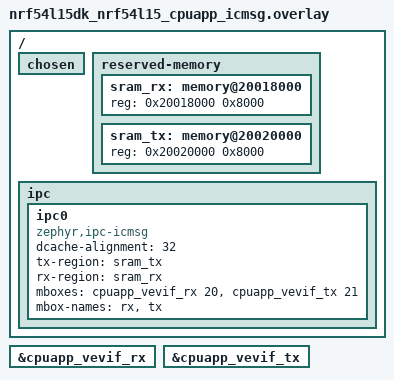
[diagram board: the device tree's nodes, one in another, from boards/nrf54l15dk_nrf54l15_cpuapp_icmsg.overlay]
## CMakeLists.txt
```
#
# Copyright (c) 2022 Nordic Semiconductor
#
# SPDX-License-Identifier: LicenseRef-Nordic-5-Clause
#

cmake_minimum_required(VERSION 3.20.0)

find_package(Zephyr REQUIRED HINTS $ENV{ZEPHYR_BASE})
project(event_manager_proxy)

add_subdirectory(common_config)
add_subdirectory(common_events)
add_subdirectory(modules)

target_include_directories(app PUBLIC ${CMAKE_CURRENT_SOURCE_DIR}/src)

target_sources(app PRIVATE
  src/test_init.c
  src/data.c
  src/simple.c
)
```

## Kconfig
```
#
# Copyright (c) 2022 Nordic Semiconductor ASA
#
# SPDX-License-Identifier: LicenseRef-Nordic-5-Clause
#

menu "Zephyr Kernel"
source "Kconfig.zephyr"
endmenu

menu "Event manager proxy test settings"

config APP_SYSTEM_INIT_PRIO
	int "The application preparation initializaition priority"
	default 0
	help
	  The priority of initialization of everything that have to happen
	  before the proxy initialation.
	  The remote core is initialized here if required.

config APP_PROXY_INIT_PRIO
	int "Proxy initialization priority"
	default 1
	help
	  The Event manager proxy initialization priority.
	  Make sure that initialization happens before registration and starting.

config APP_PROXY_REGISTER_PRIO
	int "Proxy registration priority"
	default 2
	help
	  The Event manager proxy registration priority.
	  The moment when all the modules reqisters to the required events to remote.
	  Make sure that it happens after the proxy itself is initialized but before
	  it is started.

config APP_PROXY_START_PRIO
	int "Proxy start priority"
	default 5
	help
	  The Event manager proxy starting priority.
	  The moment when Event manager is started.
	  After this time no more remote event registration is allowed.
	  Make sure that it happens after event proxy registration.

rsource "common_events/Kconfig"
endmenu
```

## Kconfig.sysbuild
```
#
# Copyright (c) 2023 Nordic Semiconductor ASA
#
# SPDX-License-Identifier: LicenseRef-Nordic-5-Clause
#

if SUPPORT_PPRCORE

choice PPRCORE
	default PPRCORE_REMOTE

config PPRCORE_REMOTE
	bool "remote image"

endchoice

config PPRCORE_IMAGE_NAME
	default "remote" if PPRCORE_REMOTE

config PPRCORE_IMAGE_PATH
	default "${APP_DIR}/remote" if PPRCORE_REMOTE

endif # SUPPORT_PPRCORE

if SUPPORT_FLPRCORE && !SUPPORT_PPRCORE

choice FLPRCORE
	default FLPRCORE_REMOTE

config FLPRCORE_REMOTE
	bool "remote image"

endchoice

config FLPRCORE_IMAGE_NAME
	default "remote" if FLPRCORE_REMOTE

config FLPRCORE_IMAGE_PATH
	default "${APP_DIR}/remote" if FLPRCORE_REMOTE

endif # SUPPORT_FLPRCORE && !SUPPORT_PPRCORE

if SUPPORT_NETCORE && !SUPPORT_FLPRCORE && !SUPPORT_PPRCORE

choice NETCORE
	default NETCORE_REMOTE

config NETCORE_REMOTE
	bool "remote image"

endchoice

config NETCORE_IMAGE_NAME
	default "remote" if NETCORE_REMOTE

config NETCORE_IMAGE_PATH
	default "${APP_DIR}/remote" if NETCORE_REMOTE

endif # SUPPORT_NETCORE && !SUPPORT_FLPRCORE && !SUPPORT_PPRCORE

source "share/sysbuild/Kconfig"
```

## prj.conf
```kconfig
#
# Copyright (c) 2022-2023 Nordic Semiconductor ASA
#
# SPDX-License-Identifier: LicenseRef-Nordic-5-Clause
#

CONFIG_ZTEST=y

CONFIG_ENTROPY_GENERATOR=y

# Configuration required by Application Event Manager
CONFIG_APP_EVENT_MANAGER=y
CONFIG_EVENT_MANAGER_PROXY=y
CONFIG_SYSTEM_WORKQUEUE_STACK_SIZE=2048
CONFIG_HEAP_MEM_POOL_SIZE=2048

CONFIG_IPC_SERVICE=y
CONFIG_MBOX=y

# Custom reboot handler is implemented for test purposes
CONFIG_RESET_ON_FATAL_ERROR=n
CONFIG_REBOOT=n

###################################
# Application configuration
###################################

CONFIG_APP_DATA_EVENT=y
CONFIG_APP_SIMPLE_EVENT=y
CONFIG_APP_TEST_EVENT=y
```

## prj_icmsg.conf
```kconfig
#
# Copyright (c) 2022-2023 Nordic Semiconductor ASA
#
# SPDX-License-Identifier: LicenseRef-Nordic-5-Clause
#

CONFIG_ZTEST=y

CONFIG_ENTROPY_GENERATOR=y

# Configuration required by Application Event Manager
CONFIG_APP_EVENT_MANAGER=y
CONFIG_EVENT_MANAGER_PROXY=y
CONFIG_SYSTEM_WORKQUEUE_STACK_SIZE=2048
CONFIG_HEAP_MEM_POOL_SIZE=2048

CONFIG_IPC_SERVICE=y
CONFIG_MBOX=y
CONFIG_PBUF_RX_READ_BUF_SIZE=512

CONFIG_EVENT_MANAGER_PROXY_SEND_RETRIES=100

# Custom reboot handler is implemented for test purposes
CONFIG_RESET_ON_FATAL_ERROR=n
CONFIG_REBOOT=n

###################################
# Application configuration
###################################

CONFIG_APP_DATA_EVENT=y
CONFIG_APP_SIMPLE_EVENT=y
CONFIG_APP_TEST_EVENT=y
```

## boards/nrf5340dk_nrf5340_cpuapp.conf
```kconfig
#
# Copyright (c) 2022 Nordic Semiconductor ASA
#
# SPDX-License-Identifier: LicenseRef-Nordic-5-Clause
#

CONFIG_SOC_NRF53_CPUNET_ENABLE=y
CONFIG_EVENT_MANAGER_PROXY_BIND_TIMEOUT_MS=4000
```

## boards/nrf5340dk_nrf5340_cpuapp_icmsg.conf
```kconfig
#
# Copyright (c) 2022 Nordic Semiconductor ASA
#
# SPDX-License-Identifier: LicenseRef-Nordic-5-Clause
#

CONFIG_SOC_NRF53_CPUNET_ENABLE=y
```

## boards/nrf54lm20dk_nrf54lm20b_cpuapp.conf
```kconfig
#
# Copyright (c) 2026 Nordic Semiconductor ASA
#
# SPDX-License-Identifier: LicenseRef-Nordic-5-Clause
#

CONFIG_EVENT_MANAGER_PROXY_BIND_TIMEOUT_MS=4000
```

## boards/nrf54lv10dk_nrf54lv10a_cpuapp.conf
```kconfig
#
# Copyright (c) 2025 Nordic Semiconductor ASA
#
# SPDX-License-Identifier: LicenseRef-Nordic-5-Clause
#

CONFIG_EVENT_MANAGER_PROXY_BIND_TIMEOUT_MS=4000
```

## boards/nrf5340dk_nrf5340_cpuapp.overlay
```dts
/*
 * Copyright (c) 2022 Nordic Semiconductor ASA
 *
 * SPDX-License-Identifier: LicenseRef-Nordic-5-Clause
 */
#include <zephyr/dt-bindings/ipc_service/static_vrings.h>

&ipc0 {
	zephyr,priority = <0 PRIO_PREEMPT>;
};
```

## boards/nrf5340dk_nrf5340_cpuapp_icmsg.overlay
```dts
/*
 * Copyright (c) 2022 Nordic Semiconductor ASA
 *
 * SPDX-License-Identifier: LicenseRef-Nordic-5-Clause
 */

/delete-node/ &ipc0;
/delete-node/ &sram0_shared;

/ {
	chosen {
		/delete-property/ zephyr,ipc_shm;
		/delete-property/ zephyr,bt-hci;
	};

	reserved-memory {
		#address-cells = <1>;
		#size-cells = <1>;
		ranges;

		sram_tx: memory@20070000 {
			reg = <0x20070000 0x0800>;
		};

		sram_rx: memory@20078000 {
			reg = <0x20078000 0x0800>;
		};
	};

	ipc0: ipc0 {
		compatible = "zephyr,ipc-icmsg";
		tx-region = <&sram_tx>;
		rx-region = <&sram_rx>;
		mboxes = <&mbox 0>, <&mbox 1>;
		mbox-names = "tx", "rx";
		status = "okay";
	};
};
```

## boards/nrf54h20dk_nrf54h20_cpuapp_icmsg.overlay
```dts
/*
 * Copyright (c) 2025 Nordic Semiconductor ASA
 *
 * SPDX-License-Identifier: LicenseRef-Nordic-5-Clause
 */

/* Replace default ipc0 instance */
/delete-node/ &ipc0;

/* Enabled nodes required by IPC
 * Mbox for PPR target, one for each side and one IPC instance
 */

&cpuppr_vevif {
	status = "okay";
};

ipc0: &cpuapp_cpuppr_ipc {
	status = "okay";
};

/ {
	chosen {
		/delete-property/ zephyr,bt-hci;
	};
};
```

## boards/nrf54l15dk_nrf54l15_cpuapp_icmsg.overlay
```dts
/*
 * Copyright (c) 2025 Nordic Semiconductor ASA
 *
 * SPDX-License-Identifier: LicenseRef-Nordic-5-Clause
 */

/ {
	chosen {
		/delete-property/ zephyr,bt-hci;
	};

	reserved-memory {
		#address-cells = <1>;
		#size-cells = <1>;
		ranges;

		sram_rx: memory@20018000 {
			reg = <0x20018000 0x8000>;
		};

		sram_tx: memory@20020000 {
			reg = <0x20020000 0x8000>;
		};
	};

	ipc {
		ipc0: ipc0 {
			compatible = "zephyr,ipc-icmsg";
			/delete-property/ tx-blocks;
			/delete-property/ rx-blocks;
			dcache-alignment = <32>;
			tx-region = <&sram_tx>;
			rx-region = <&sram_rx>;
			mboxes = <&cpuapp_vevif_rx 20>, <&cpuapp_vevif_tx 21>;
			mbox-names = "rx", "tx";
			status = "okay";
		};
	};
};

&cpuapp_vevif_rx {
	status = "okay";
};

&cpuapp_vevif_tx {
	status = "okay";
};
```

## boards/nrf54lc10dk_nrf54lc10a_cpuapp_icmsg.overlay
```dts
/*
 * Copyright (c) 2026 Nordic Semiconductor ASA
 *
 * SPDX-License-Identifier: LicenseRef-Nordic-5-Clause
 */

/ {
	chosen {
		/delete-property/ zephyr,bt-hci;
	};

	reserved-memory {
		#address-cells = <1>;
		#size-cells = <1>;
		ranges;

		sram_rx: memory@2000fc00 {
			reg = <0x2000fc00 0x8000>;
		};

		sram_tx: memory@20017c00 {
			reg = <0x20017c00 0x8000>;
		};
	};

	ipc {
		ipc0: ipc0 {
			compatible = "zephyr,ipc-icmsg";
			dcache-alignment = <32>;
			tx-region = <&sram_tx>;
			rx-region = <&sram_rx>;
			mboxes = <&cpuapp_vevif_rx 20>, <&cpuapp_vevif_tx 21>;
			mbox-names = "rx", "tx";
			status = "okay";
		};
	};
};

&cpuapp_vevif_rx {
	status = "okay";
};

&cpuapp_vevif_tx {
	status = "okay";
};
```

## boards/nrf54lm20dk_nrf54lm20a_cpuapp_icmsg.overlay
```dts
/*
 * Copyright (c) 2025 Nordic Semiconductor ASA
 *
 * SPDX-License-Identifier: LicenseRef-Nordic-5-Clause
 */

/ {
	chosen {
		/delete-property/ zephyr,bt-hci;
	};

	reserved-memory {
		#address-cells = <1>;
		#size-cells = <1>;
		ranges;

		sram_rx: memory@20057c00 {
			reg = <0x20057c00 0x8000>;
		};

		sram_tx: memory@2005fc00 {
			reg = <0x2005fc00 0x8000>;
		};
	};

	ipc {
		ipc0: ipc0 {
			compatible = "zephyr,ipc-icmsg";
			/delete-property/ tx-blocks;
			/delete-property/ rx-blocks;
			dcache-alignment = <32>;
			tx-region = <&sram_tx>;
			rx-region = <&sram_rx>;
			mboxes = <&cpuapp_vevif_rx 20>, <&cpuapp_vevif_tx 21>;
			mbox-names = "rx", "tx";
			status = "okay";
		};
	};
};

&cpuapp_vevif_rx {
	status = "okay";
};

&cpuapp_vevif_tx {
	status = "okay";
};
```

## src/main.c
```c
/*
 * Copyright (c) 2022 Nordic Semiconductor ASA
 *
 * SPDX-License-Identifier: LicenseRef-Nordic-5-Clause
 */
#include <zephyr/ztest.h>

#include <app_event_manager.h>
#include <event_manager_proxy.h>

#include "test_config.h"
#include "common_utils.h"
#include "simple.h"
#include "data.h"
#include "test_events.h"

void test_initialization(void)
{
	int ret;
	const struct device *ipc_instance  = REMOTE_IPC_DEV;

	ret = app_event_manager_init();
	zassert_ok(ret, "Event manager init failed (%d)", ret);

	ret = event_manager_proxy_add_remote(ipc_instance);
	zassert_ok(ret, "Cannot add remote (%d)", ret);

	REMOTE_EVENT_SUBSCRIBE_TEST(ipc_instance, test_end_remote_event);
	REMOTE_EVENT_SUBSCRIBE_TEST(ipc_instance, test_start_ack_event);

	simple_register();
	data_register();

	ret = event_manager_proxy_start();
	zassert_ok(ret, "Cannot start event manager proxy (%d)", ret);

	ret = event_manager_proxy_wait_for_remotes(K_SECONDS(REMOTE_START_TIMEOUT_S));
	zassert_ok(ret, "Error when waiting for remote (%d)", ret);
}


void test_main(void)
{
	ztest_test_suite(test_init,
			 ztest_unit_test(test_initialization)
			 );

	ztest_run_test_suite(test_init);

	simple_run();
	data_run();
}
```

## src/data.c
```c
/*
 * Copyright (c) 2022 Nordic Semiconductor ASA
 *
 * SPDX-License-Identifier: LicenseRef-Nordic-5-Clause
 */
#include <zephyr/ztest.h>
#include <zephyr/random/random.h>
#include <zephyr/syscalls/random.h>

#include <app_event_manager.h>
#include <event_manager_proxy.h>

#include "test_config.h"
#include "common_utils.h"
#include "test_utils.h"
#include "data_events.h"

#define MODULE test_data

#include <zephyr/logging/log.h>
LOG_MODULE_REGISTER(MODULE);

static K_SEM_DEFINE(waiting_response_sem, 0, 1);

struct data_content {
	int8_t val1;
	int16_t val2;
	int32_t val3;
	uint8_t val1u;
	uint16_t val2u;
	uint32_t val3u;
};

struct data_big_content {
	uint32_t block[DATA_BIG_EVENT_BLOCK_SIZE];
};

static struct data_content data_response;
static struct data_big_content data_big_response;

ZTEST(data_tests, test_data_response)
{
	struct data_event *event = new_data_event();
	struct data_content rand_test_data;

	rand_test_data.val1 = event->val1 = (int8_t)sys_rand32_get();
	rand_test_data.val2 = event->val2 = (int8_t)sys_rand32_get();
	rand_test_data.val3 = event->val3 = (int8_t)sys_rand32_get();
	rand_test_data.val1u = event->val1u = (uint8_t)sys_rand32_get();
	rand_test_data.val2u = event->val2u = (uint8_t)sys_rand32_get();
	rand_test_data.val3u = event->val3u = (uint8_t)sys_rand32_get();

	memset(&data_response, 0, sizeof(data_response));
	k_sem_reset(&waiting_response_sem);
	test_start(TEST_DATA_RESPONSE);

	APP_EVENT_SUBMIT(event);

	int err = k_sem_take(&waiting_response_sem, K_SECONDS(RESPONSE_TIMEOUT_S));
	zassert_ok(err, "No data response event received");

	zassert_equal(rand_test_data.val1, data_response.val1, "Unexpected value in response");
	zassert_equal(rand_test_data.val2, data_response.val2, "Unexpected value in response");
	zassert_equal(rand_test_data.val3, data_response.val3, "Unexpected value in response");
	zassert_equal(rand_test_data.val1u, data_response.val1u, "Unexpected value in response");
	zassert_equal(rand_test_data.val2u, data_response.val2u, "Unexpected value in response");
	zassert_equal(rand_test_data.val3u, data_response.val3u, "Unexpected value in response");

	test_end(TEST_DATA_RESPONSE);
}

ZTEST(data_tests, test_data_big_response)
{
	struct data_big_event *event = new_data_big_event();
	struct data_big_content rand_test_data;

	for (size_t i = 0; i < DATA_BIG_EVENT_BLOCK_SIZE; i++) {
		event->block[i] = sys_rand32_get();
	}

	memset(&data_big_response, 0, sizeof(data_big_response));
	zassert_equal(sizeof(event->block), sizeof(rand_test_data.block), "Wrong data size");
	memcpy(&rand_test_data.block, &event->block, sizeof(event->block));
	k_sem_reset(&waiting_response_sem);
	test_start(TEST_DATA_RESPONSE);

	APP_EVENT_SUBMIT(event);

	int err = k_sem_take(&waiting_response_sem, K_SECONDS(RESPONSE_TIMEOUT_S));
	zassert_ok(err, "No data response event received");

	zassert_mem_equal(&data_big_response.block,
			  &rand_test_data.block,
			  sizeof(data_big_response.block),
			  "Unexpected block in response");

	test_end(TEST_DATA_RESPONSE);
}

ZTEST(data_tests, test_data_burst)
{
	uint32_t us_spent;

	test_start(TEST_DATA_BURST);
	test_start_ack_wait();

	test_time_start();

	proxy_burst_data_events();
	test_end_wait(TEST_DATA_BURST);

	us_spent = test_time_spent_us();

	unsigned long speed =
				     /* Burst size + test end event */
		((uint64_t)Z_HZ_us * (TEST_CONFIG_DATA_BURST_SIZE + 1)) /
		us_spent;
	printk(" Time: %u us\n", us_spent);
	printk(" Test sending data burst speed %lu msg/sec\n", speed);
}

ZTEST(data_tests, test_data_burst_from_remote)
{
	uint32_t us_spent;

	test_start(TEST_DATA_BURST_FROM_REMOTE);
	test_start_ack_wait();
	test_time_start();
	test_end_wait(TEST_DATA_BURST_FROM_REMOTE);

	us_spent = test_time_spent_us();

	unsigned long speed =
				     /* Burst size + test end event */
		((uint64_t)Z_HZ_us * (TEST_CONFIG_DATA_BURST_SIZE + 1)) /
		us_spent;

	printk(" Time: %u us\n", us_spent);
	printk(" Test receiving data burst speed %lu msg/sec\n", speed);
}

ZTEST(data_tests, test_data_ping_pong_performance)
{
	uint32_t us_spent;
	int err;
	struct data_event *event = new_data_event();

	memset(&data_response, -1, sizeof(data_response));
	k_sem_reset(&waiting_response_sem);
	test_start(TEST_DATA_RESPONSE);
	test_start_ack_wait();
	test_time_start();

	for (size_t cnt = 0; cnt < TEST_CONFIG_DATA_BURST_SIZE; ++cnt) {
		event->val1 = (int8_t)cnt;
		event->val2 = (int16_t)cnt;
		event->val3 = (int32_t)cnt;
		event->val1u = (uint8_t)cnt;
		event->val2u = (uint16_t)cnt;
		event->val3u = (uint32_t)cnt;

		proxy_direct_submit_event(&event->header);
		err = k_sem_take(&waiting_response_sem, K_SECONDS(RESPONSE_TIMEOUT_S));
		zassert_ok(err, "No data event received");

		zassert_equal(event->val1, data_response.val1, "Unexpected value in response");
		zassert_equal(event->val2, data_response.val2, "Unexpected value in response");
		zassert_equal(event->val3, data_response.val3, "Unexpected value in response");
		zassert_equal(event->val1u, data_response.val1u, "Unexpected value in response");
		zassert_equal(event->val2u, data_response.val2u, "Unexpected value in response");
		zassert_equal(event->val3u, data_response.val3u, "Unexpected value in response");
	}

	us_spent = test_time_spent_us();

	app_event_manager_free(event);

	test_end(TEST_DATA_RESPONSE);

	unsigned long speed =
				     /* Burst size + test end event */
		((uint64_t)Z_HZ_us * (TEST_CONFIG_DATA_BURST_SIZE + 1)) /
		us_spent;

	printk(" Time: %u us\n", us_spent);
	printk(" Test data ping pong speed %lu msg/sec\n", speed);
}

ZTEST(data_tests, test_data_big_burst)
{
	uint32_t us_spent;

	test_start(TEST_DATA_BIG_BURST);
	test_start_ack_wait();

	test_time_start();

	proxy_burst_data_big_events();
	test_end_wait(TEST_DATA_BIG_BURST);

	us_spent = test_time_spent_us();

	unsigned long speed =
				     /* Burst size + test end event */
		((uint64_t)Z_HZ_us * (TEST_CONFIG_DATA_BIG_BURST_SIZE + 1)) /
		us_spent;
	printk(" Time: %u us\n", us_spent);
	printk(" Test sending data big burst speed %lu msg/sec\n", speed);
}

ZTEST(data_tests, test_data_big_burst_from_remote)
{
	uint32_t us_spent;

	test_start(TEST_DATA_BIG_BURST_FROM_REMOTE);
	test_start_ack_wait();
	test_time_start();
	test_end_wait(TEST_DATA_BIG_BURST_FROM_REMOTE);

	us_spent = test_time_spent_us();

	unsigned long speed =
				     /* Burst size + test end event */
		((uint64_t)Z_HZ_us * (TEST_CONFIG_DATA_BIG_BURST_SIZE + 1)) /
		us_spent;

	printk(" Time: %u us\n", us_spent);
	printk(" Test receiving data big burst speed %lu msg/sec\n", speed);
}

ZTEST(data_tests, test_data_big_ping_pong_performance)
{
	uint32_t us_spent;
	int err;
	struct data_big_event *event = new_data_big_event();

	memset(&data_response, -1, sizeof(data_response));
	k_sem_reset(&waiting_response_sem);
	test_start(TEST_DATA_RESPONSE);
	test_start_ack_wait();
	test_time_start();

	for (size_t cnt = 0; cnt < TEST_CONFIG_DATA_BIG_BURST_SIZE; ++cnt) {
		for(size_t n = 0; n < DATA_BIG_EVENT_BLOCK_SIZE; ++n) {
			event->block[n] = cnt + n;
		}

		proxy_direct_submit_event(&event->header);
		err = k_sem_take(&waiting_response_sem, K_SECONDS(RESPONSE_TIMEOUT_S));
		zassert_ok(err, "No data event received");

		zassert_mem_equal(&data_big_response.block, &event->block, sizeof(event->block),
				  "Unexpected block in response");
	}

	us_spent = test_time_spent_us();

	app_event_manager_free(event);

	test_end(TEST_DATA_RESPONSE);

	unsigned long speed =
				     /* Burst size + test end event */
		((uint64_t)Z_HZ_us * (TEST_CONFIG_DATA_BIG_BURST_SIZE + 1)) /
		us_spent;

	printk(" Time: %u us\n", us_spent);
	printk(" Test data big ping pong speed %lu msg/sec\n", speed);
}

static bool data_event_handler(const struct app_event_header *aeh)
{
	if (is_data_response_event(aeh)) {
		struct data_response_event *event = cast_data_response_event(aeh);

		data_response.val1 = event->val1;
		data_response.val2 = event->val2;
		data_response.val3 = event->val3;
		data_response.val1u = event->val1u;
		data_response.val2u = event->val2u;
		data_response.val3u = event->val3u;

		k_sem_give(&waiting_response_sem);
		return false;
	} else if (is_data_big_response_event(aeh)) {
		struct data_big_response_event *event = cast_data_big_response_event(aeh);

		memcpy(&data_big_response.block, &event->block, sizeof(data_big_response.block));
		k_sem_give(&waiting_response_sem);
		return false;
	}

	zassert_true(false, "Wrong event type received");
	return false;
}

APP_EVENT_LISTENER(MODULE, data_event_handler);
APP_EVENT_SUBSCRIBE(MODULE, data_response_event);
APP_EVENT_SUBSCRIBE(MODULE, data_big_response_event);

static int test_data_events_register(void)
{
	const struct device *ipc_instance  = REMOTE_IPC_DEV;

	REMOTE_EVENT_SUBSCRIBE(ipc_instance, data_response_event);
	REMOTE_EVENT_SUBSCRIBE(ipc_instance, data_big_response_event);

	return 0;
}

SYS_INIT(test_data_events_register, APPLICATION, CONFIG_APP_PROXY_REGISTER_PRIO);

ZTEST_SUITE(data_tests, NULL, NULL, NULL, NULL, NULL);
```

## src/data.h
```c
/*
 * Copyright (c) 2022 Nordic Semiconductor ASA
 *
 * SPDX-License-Identifier: LicenseRef-Nordic-5-Clause
 */

#ifndef _DATA_H_
#define _DATA_H_

void data_register(void);
void data_run(void);

#endif /* _DATA_H_ */
```

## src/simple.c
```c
/*
 * Copyright (c) 2022 Nordic Semiconductor ASA
 *
 * SPDX-License-Identifier: LicenseRef-Nordic-5-Clause
 */
#include <zephyr/ztest.h>

#include <app_event_manager.h>
#include <event_manager_proxy.h>

#include "test_config.h"
#include "common_utils.h"
#include "test_utils.h"
#include "simple_events.h"

#define MODULE test_simple

#include <zephyr/logging/log.h>
LOG_MODULE_REGISTER(MODULE);

static K_SEM_DEFINE(waiting_pong_sem, 0, 1);


ZTEST(simple_tests, test_simple_ping_pong)
{
	struct simple_ping_event *ping = new_simple_ping_event();

	k_sem_reset(&waiting_pong_sem);
	APP_EVENT_SUBMIT(ping);

	int err = k_sem_take(&waiting_pong_sem, K_SECONDS(1));
	zassert_ok(err, "No pong event received");
}

ZTEST(simple_tests, test_simple_burst)
{
	uint32_t us_spent;

	test_start(TEST_SIMPLE_BURST);
	test_start_ack_wait();

	test_time_start();

	proxy_burst_simple_events();
	test_end_wait(TEST_SIMPLE_BURST);

	us_spent = test_time_spent_us();

	unsigned long speed =
				     /* Burst size + test end event */
		((uint64_t)Z_HZ_us * (TEST_CONFIG_SIMPLE_BURST_SIZE + 1)) /
		us_spent;
	printk(" Time: %u us\n", us_spent);
	printk(" Test sending simple burst speed %lu msg/sec\n", speed);
}

ZTEST(simple_tests, test_simple_burst_from_remote)
{
	uint32_t us_spent;

	test_time_start();

	test_start(TEST_SIMPLE_BURST_FROM_REMOTE);
	test_start_ack_wait();
	test_time_start();
	test_end_wait(TEST_SIMPLE_BURST_FROM_REMOTE);

	us_spent = test_time_spent_us();

	unsigned long speed =
				     /* Burst size + test end event */
		((uint64_t)Z_HZ_us * (TEST_CONFIG_SIMPLE_BURST_SIZE + 1)) /
		us_spent;

	printk(" Time: %u us\n", us_spent);
	printk(" Test receiving simple burst speed %lu msg/sec\n", speed);
}

ZTEST(simple_tests, test_simple_ping_pong_performance)
{
	uint32_t us_spent;
	int err;
	struct simple_ping_event *event = new_simple_ping_event();

	k_sem_reset(&waiting_pong_sem);

	test_time_start();

	for (size_t cnt = 0; cnt < TEST_CONFIG_SIMPLE_BURST_SIZE; ++cnt) {
		proxy_direct_submit_event(&event->header);
		err = k_sem_take(&waiting_pong_sem, K_SECONDS(1));
		zassert_ok(err, "No pong event received");
	}

	us_spent = test_time_spent_us();

	app_event_manager_free(event);

	unsigned long speed =
				     /* Burst size + test end event */
		((uint64_t)Z_HZ_us * (TEST_CONFIG_SIMPLE_BURST_SIZE + 1)) /
		us_spent;

	printk(" Time: %u us\n", us_spent);
	printk(" Test ping pong speed %lu msg/sec\n", speed);
}

static bool simple_event_handler(const struct app_event_header *aeh)
{
	if (is_simple_pong_event(aeh)) {
		k_sem_give(&waiting_pong_sem);
		return false;
	}

	zassert_true(false, "Wrong event type received");
	return false;
}

APP_EVENT_LISTENER(MODULE, simple_event_handler);
APP_EVENT_SUBSCRIBE(MODULE, simple_pong_event);

int test_simple_events_register(void)
{
	const struct device *ipc_instance  = REMOTE_IPC_DEV;

	REMOTE_EVENT_SUBSCRIBE(ipc_instance, simple_pong_event);

	return 0;
}

SYS_INIT(test_simple_events_register, APPLICATION, CONFIG_APP_PROXY_REGISTER_PRIO);

ZTEST_SUITE(simple_tests, NULL, NULL, NULL, NULL, NULL);
```

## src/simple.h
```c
/*
 * Copyright (c) 2022 Nordic Semiconductor ASA
 *
 * SPDX-License-Identifier: LicenseRef-Nordic-5-Clause
 */

#ifndef _SIMPLE_H_
#define _SIMPLE_H_

void simple_register(void);
void simple_run(void);

#endif /* _SIMPLE_H_ */
```

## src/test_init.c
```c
/*
 * Copyright (c) 2022 Nordic Semiconductor ASA
 *
 * SPDX-License-Identifier: LicenseRef-Nordic-5-Clause
 */
#include <zephyr/ztest.h>

#include <app_event_manager.h>
#include <event_manager_proxy.h>

#include "test_config.h"
#include "common_utils.h"
#include "test_events.h"

#define MODULE test_init

#include <zephyr/logging/log.h>
LOG_MODULE_REGISTER(MODULE);


static int test_event_manager_proxy_init(void)
{
	int ret;
	const struct device *ipc_instance  = REMOTE_IPC_DEV;

	ret = app_event_manager_init();
	__ASSERT(ret >= 0, "Event manager init failed (%d)", ret);

	ret = event_manager_proxy_add_remote(ipc_instance);
	__ASSERT(ret >= 0, "Cannot add remote (%d)", ret);

	REMOTE_EVENT_SUBSCRIBE(ipc_instance, test_end_remote_event);
	REMOTE_EVENT_SUBSCRIBE(ipc_instance, test_start_ack_event);

	return 0;
}

SYS_INIT(test_event_manager_proxy_init, APPLICATION, CONFIG_APP_PROXY_INIT_PRIO);

static int test_event_manager_proxy_start(void)
{
	int ret;

	ret = event_manager_proxy_start();
	__ASSERT(ret >= 0, "Cannot start event manager proxy (%d)", ret);

	ret = event_manager_proxy_wait_for_remotes(K_SECONDS(REMOTE_START_TIMEOUT_S));
	__ASSERT(ret >= 0, "Error when waiting for remote (%d)", ret);

	return 0;
}

SYS_INIT(test_event_manager_proxy_start, APPLICATION, CONFIG_APP_PROXY_START_PRIO);
```
